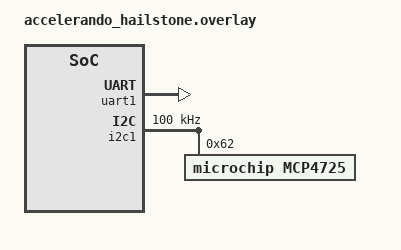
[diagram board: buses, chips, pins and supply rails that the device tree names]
/ {
	chosen {
		zephyr,console = &uart1;
		zephyr,shell-uart = &uart1;
		zephyr,uart-mcumgr = &uart1;
	};

	aliases {
		dac0 = &mcp4725;
	};
};

&uart1 {
	status = "okay";
};

&i2c0 {
	status = "disabled";
};

&i2c1 {
	status = "okay";
        clock-frequency = <I2C_BITRATE_STANDARD>;

        mcp4725: mcp4725@62 {
                status = "okay";
                compatible = "microchip,mcp4725";
                reg = <0x62>;
                #io-channel-cells = <1>;
        };

};

&spi1 {
  status = "disabled";
};

